# RX64M_MTU_Pilot register map
File version: 1.0
RX64M_MTU_Pilot peripheral registers generated from iodefine.h (pilot).
Registers are 8-bit, read-write, reset 0x0 unless marked. A register's access mark holds for its fields unless they carry their own. Offsets are from the block's base; lines under a group give offsets from that group; [hi:lo] are bit positions; {n}, {i} and the like mark numbered series; 'fields as' and 'values as' point back to an identical list; <NAME> marks a mode.

## Memory map
0x000C1200 MTU3 size 0x94
0x000C1200 MTU4 size 0x95
0x000C120A MTU size 0x87B
0x000C1290 MTU0 size 0x99
0x000C1290 MTU1 size 0x11C
0x000C1292 MTU2 size 0x17B
0x000C1A00 MTU6 size 0x94
0x000C1A00 MTU7 size 0x95
0x000C1A94 MTU5 size 0x223

## MTU
Base 0x000C120A
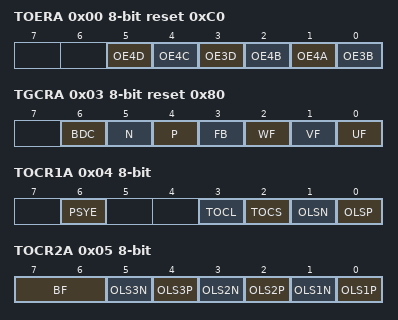
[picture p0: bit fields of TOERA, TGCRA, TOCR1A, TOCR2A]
0x00 TOERA reset 0xC0
  [5] OE4D, [4] OE4C, [3] OE3D, [2] OE4B, [1] OE4A, [0] OE3B
0x03 TGCRA reset 0x80
  [6] BDC, [5] N, [4] P, [3] FB, [2] WF, [1] VF, [0] UF
0x04 TOCR1A
  [6] PSYE, [3] TOCL, [2] TOCS, [1] OLSN, [0] OLSP
0x05 TOCR2A
  [7:6] BF, [5] OLS3N, [4] OLS3P, [3] OLS2N, [2] OLS2P, [1] OLS1N, [0] OLS1P
0x0A TCDRA 16-bit reset 0xFFFF
0x0C TDDRA 16-bit reset 0xFFFF
0x16 TCNTSA 16-bit ro
0x18 TCBRA 16-bit reset 0xFFFF
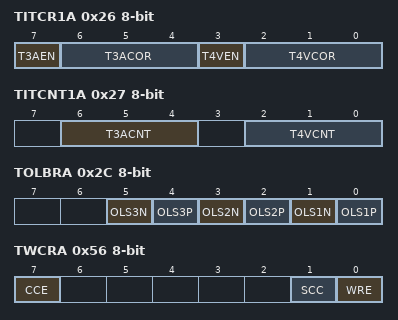
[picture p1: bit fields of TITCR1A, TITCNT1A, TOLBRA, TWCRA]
0x26 TITCR1A
  [7] T3AEN, [6:4] T3ACOR, [3] T4VEN, [2:0] T4VCOR
0x27 TITCNT1A ro
  [6:4] T3ACNT, [2:0] T4VCNT
0x28 TBTERA
  [1:0] BTE
0x2A TDERA reset 0x1
  [0] TDER
0x2C TOLBRA
  [5] OLS3N, [4] OLS3P, [3] OLS2N, [2] OLS2P, [1] OLS1N, [0] OLS1P
0x30 TITMRA
  [0] TITM
0x31 TITCR2A
  [2:0] TRG4COR
0x32 TITCNT2A ro
  [2:0] TRG4CNT
0x56 TWCRA
  [7] CCE, [1] SCC, [0] WRE
0x66 TMDR2A
  [0] DRS
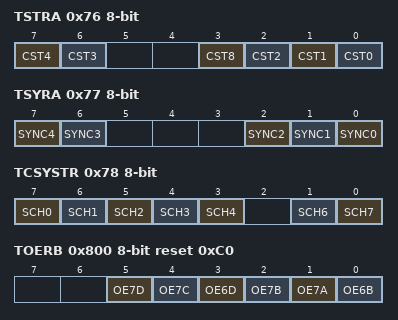
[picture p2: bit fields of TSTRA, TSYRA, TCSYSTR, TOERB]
0x76 TSTRA
  [7] CST4, [6] CST3, [3] CST8, [2] CST2, [1] CST1, [0] CST0
0x77 TSYRA
  [7] SYNC4, [6] SYNC3, [2] SYNC2, [1] SYNC1, [0] SYNC0
0x78 TCSYSTR
  [7-n] SCH{n} (n=0..4), [1] SCH6, [0] SCH7
0x7A TRWERA reset 0x1
  [0] RWE
0x800 TOERB reset 0xC0
  [5] OE7D, [4] OE7C, [3] OE6D, [2] OE7B, [1] OE7A, [0] OE6B
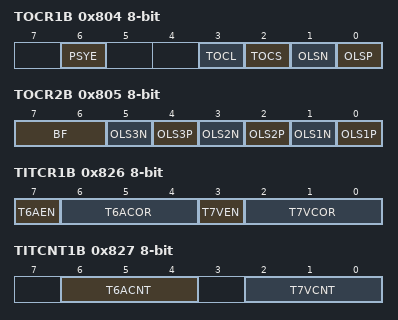
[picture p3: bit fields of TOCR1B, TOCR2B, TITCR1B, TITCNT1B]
0x804 TOCR1B
  [6] PSYE, [3] TOCL, [2] TOCS, [1] OLSN, [0] OLSP
0x805 TOCR2B
  fields as TOCR2A
0x80A TCDRB 16-bit reset 0xFFFF
0x80C TDDRB 16-bit reset 0xFFFF
0x816 TCNTSB 16-bit ro
0x818 TCBRB 16-bit reset 0xFFFF
0x826 TITCR1B
  [7] T6AEN, [6:4] T6ACOR, [3] T7VEN, [2:0] T7VCOR
0x827 TITCNT1B ro
  [6:4] T6ACNT, [2:0] T7VCNT
0x828 TBTERB
  [1:0] BTE
0x82A TDERB reset 0x1
  [0] TDER
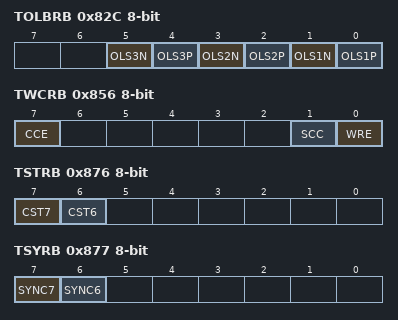
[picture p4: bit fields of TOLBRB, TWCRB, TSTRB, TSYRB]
0x82C TOLBRB
  [5] OLS3N, [4] OLS3P, [3] OLS2N, [2] OLS2P, [1] OLS1N, [0] OLS1P
0x830 TITMRB
  [0] TITM
0x831 TITCR2B
  [2:0] TRG7COR
0x832 TITCNT2B ro
  [2:0] TRG7CNT
0x856 TWCRB
  [7] CCE, [1] SCC, [0] WRE
0x866 TMDR2B
  [0] DRS
0x876 TSTRB
  [7] CST7, [6] CST6
0x877 TSYRB
  [7] SYNC7, [6] SYNC6
0x87A TRWERB reset 0x1
  [0] RWE

## MTU0
Base 0x000C1290
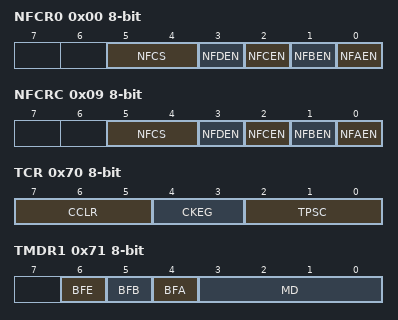
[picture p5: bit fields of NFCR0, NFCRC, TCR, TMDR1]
0x00 NFCR0
  [5:4] NFCS, [3] NFDEN, [2] NFCEN, [1] NFBEN, [0] NFAEN
0x09 NFCRC
  [5:4] NFCS, [3] NFDEN, [2] NFCEN, [1] NFBEN, [0] NFAEN
0x70 TCR
  [7:5] CCLR, [4:3] CKEG, [2:0] TPSC
0x71 TMDR1
  [6] BFE, [5] BFB, [4] BFA, [3:0] MD
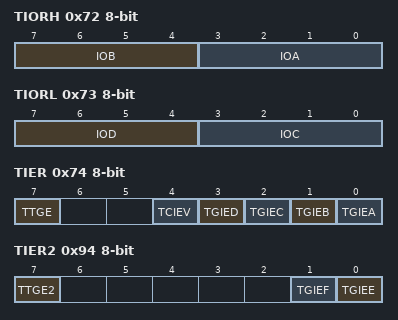
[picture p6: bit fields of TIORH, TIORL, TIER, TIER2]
0x72 TIORH
  [7:4] IOB, [3:0] IOA
0x73 TIORL
  [7:4] IOD, [3:0] IOC
0x74 TIER
  [7] TTGE, [4] TCIEV, [3] TGIED, [2] TGIEC, [1] TGIEB, [0] TGIEA
0x76 TCNT 16-bit
0x78 TGRA 16-bit reset 0xFFFF
0x7A TGRB 16-bit reset 0xFFFF
0x7C TGRC 16-bit reset 0xFFFF
0x7E TGRD 16-bit reset 0xFFFF
0x90 TGRE 16-bit reset 0xFFFF
0x92 TGRF 16-bit reset 0xFFFF
0x94 TIER2
  [7] TTGE2, [1] TGIEF, [0] TGIEE
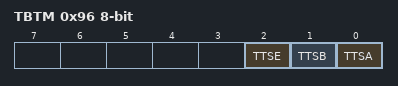
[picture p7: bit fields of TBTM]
0x96 TBTM
  [2] TTSE, [1] TTSB, [0] TTSA
0x98 TCR2
  [2:0] TPSC2

## MTU1
Base 0x000C1290; alternate view of MTU0
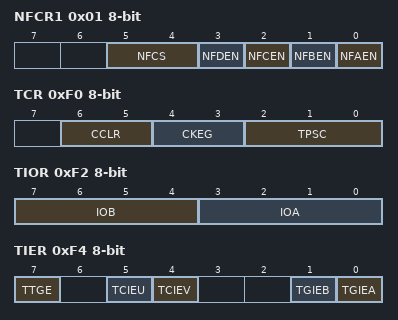
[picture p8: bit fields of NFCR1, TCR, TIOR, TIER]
0x01 NFCR1
  [5:4] NFCS, [3] NFDEN, [2] NFCEN, [1] NFBEN, [0] NFAEN
0xF0 TCR
  [6:5] CCLR, [4:3] CKEG, [2:0] TPSC
0xF1 TMDR1
  [3:0] MD
0xF2 TIOR
  [7:4] IOB, [3:0] IOA
0xF4 TIER
  [7] TTGE, [5] TCIEU, [4] TCIEV, [1] TGIEB, [0] TGIEA
0xF5 TSR reset 0xC0
  [7] TCFD
0xF6 TCNT 16-bit
0xF8 TGRA 16-bit reset 0xFFFF
0xFA TGRB 16-bit reset 0xFFFF
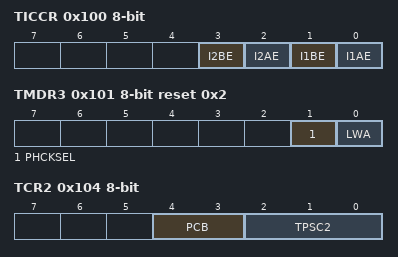
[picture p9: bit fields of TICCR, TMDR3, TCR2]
0x100 TICCR
  [3] I2BE, [2] I2AE, [1] I1BE, [0] I1AE
0x101 TMDR3 reset 0x2
  [1] PHCKSEL, [0] LWA
0x104 TCR2
  [4:3] PCB, [2:0] TPSC2
0x110 TCNTLW 32-bit
0x114 TGRALW 32-bit reset 0xFFFFFFFF
0x118 TGRBLW 32-bit reset 0xFFFFFFFF

## MTU2
Base 0x000C1292
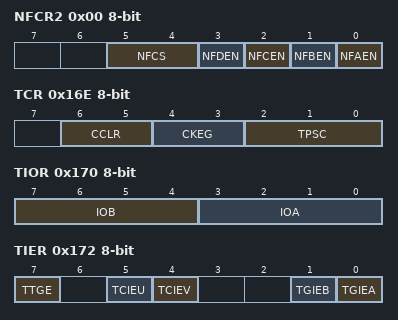
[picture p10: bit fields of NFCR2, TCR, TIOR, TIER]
0x00 NFCR2
  [5:4] NFCS, [3] NFDEN, [2] NFCEN, [1] NFBEN, [0] NFAEN
0x16E TCR
  [6:5] CCLR, [4:3] CKEG, [2:0] TPSC
0x16F TMDR1
  [3:0] MD
0x170 TIOR
  [7:4] IOB, [3:0] IOA
0x172 TIER
  [7] TTGE, [5] TCIEU, [4] TCIEV, [1] TGIEB, [0] TGIEA
0x173 TSR reset 0xC0
  [7] TCFD
0x174 TCNT 16-bit
0x176 TGRA 16-bit reset 0xFFFF
0x178 TGRB 16-bit reset 0xFFFF
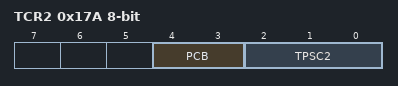
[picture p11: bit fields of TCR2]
0x17A TCR2
  [4:3] PCB, [2:0] TPSC2

## MTU3
Base 0x000C1200
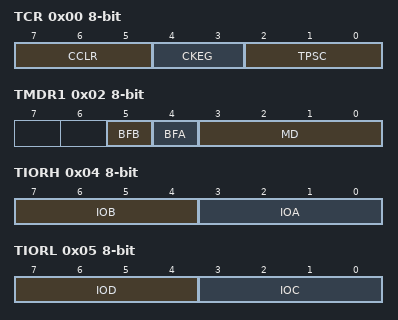
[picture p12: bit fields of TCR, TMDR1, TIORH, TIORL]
0x00 TCR
  [7:5] CCLR, [4:3] CKEG, [2:0] TPSC
0x02 TMDR1
  [5] BFB, [4] BFA, [3:0] MD
0x04 TIORH
  [7:4] IOB, [3:0] IOA
0x05 TIORL
  [7:4] IOD, [3:0] IOC
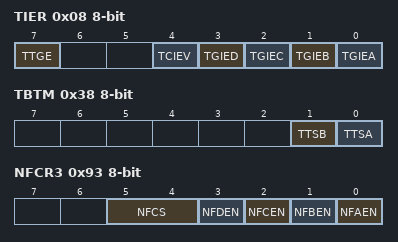
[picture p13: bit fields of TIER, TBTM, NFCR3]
0x08 TIER
  [7] TTGE, [4] TCIEV, [3] TGIED, [2] TGIEC, [1] TGIEB, [0] TGIEA
0x10 TCNT 16-bit
0x18 TGRA 16-bit reset 0xFFFF
0x1A TGRB 16-bit reset 0xFFFF
0x24 TGRC 16-bit reset 0xFFFF
0x26 TGRD 16-bit reset 0xFFFF
0x2C TSR reset 0xC0
  [7] TCFD
0x38 TBTM
  [1] TTSB, [0] TTSA
0x4C TCR2
  [2:0] TPSC2
0x72 TGRE 16-bit reset 0xFFFF
0x93 NFCR3
  [5:4] NFCS, [3] NFDEN, [2] NFCEN, [1] NFBEN, [0] NFAEN

## MTU4
Base 0x000C1200; alternate view of MTU3
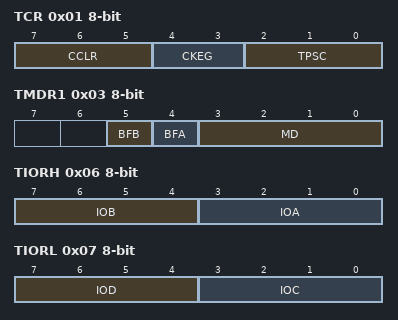
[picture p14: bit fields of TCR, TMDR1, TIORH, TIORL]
0x01 TCR
  [7:5] CCLR, [4:3] CKEG, [2:0] TPSC
0x03 TMDR1
  [5] BFB, [4] BFA, [3:0] MD
0x06 TIORH
  [7:4] IOB, [3:0] IOA
0x07 TIORL
  [7:4] IOD, [3:0] IOC
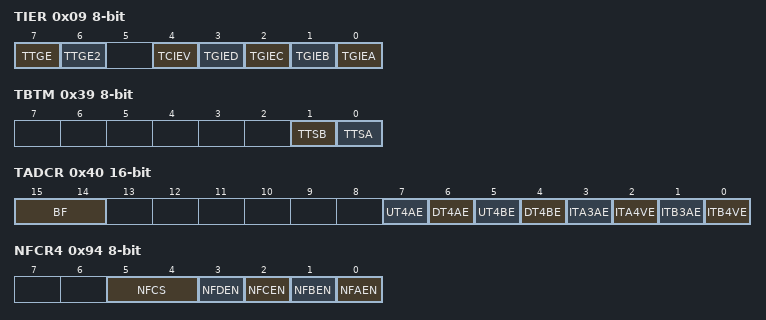
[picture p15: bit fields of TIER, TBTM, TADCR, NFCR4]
0x09 TIER
  [7] TTGE, [6] TTGE2, [4] TCIEV, [3] TGIED, [2] TGIEC, [1] TGIEB, [0] TGIEA
0x12 TCNT 16-bit
0x1C TGRA 16-bit reset 0xFFFF
0x1E TGRB 16-bit reset 0xFFFF
0x28 TGRC 16-bit reset 0xFFFF
0x2A TGRD 16-bit reset 0xFFFF
0x2D TSR reset 0xC0
  [7] TCFD
0x39 TBTM
  [1] TTSB, [0] TTSA
0x40 TADCR 16-bit
  [15:14] BF, [7] UT4AE, [6] DT4AE, [5] UT4BE, [4] DT4BE, [3] ITA3AE, [2] ITA4VE, [1] ITB3AE, [0] ITB4VE
0x44 TADCORA 16-bit reset 0xFFFF
0x46 TADCORB 16-bit reset 0xFFFF
0x48 TADCOBRA 16-bit reset 0xFFFF
0x4A TADCOBRB 16-bit reset 0xFFFF
0x4D TCR2
  [2:0] TPSC2
0x74 TGRE 16-bit reset 0xFFFF
0x76 TGRF 16-bit reset 0xFFFF
0x94 NFCR4
  [5:4] NFCS, [3] NFDEN, [2] NFCEN, [1] NFBEN, [0] NFAEN

## MTU5
Base 0x000C1A94
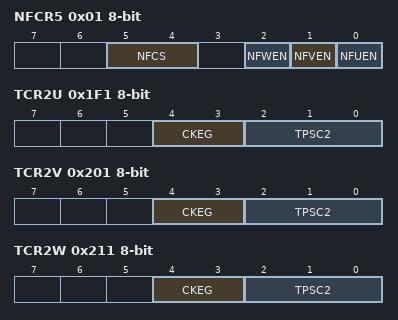
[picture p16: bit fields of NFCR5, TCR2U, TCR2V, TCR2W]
0x01 NFCR5
  [5:4] NFCS, [2] NFWEN, [1] NFVEN, [0] NFUEN
0x1EC TCNTU 16-bit
0x1EE TGRU 16-bit reset 0xFFFF
0x1F0 TCRU
  [1:0] TPSC
0x1F1 TCR2U
  [4:3] CKEG, [2:0] TPSC2
0x1F2 TIORU
  [4:0] IOC
0x1FC TCNTV 16-bit
0x1FE TGRV 16-bit reset 0xFFFF
0x200 TCRV
  [1:0] TPSC
0x201 TCR2V
  [4:3] CKEG, [2:0] TPSC2
0x202 TIORV
  [4:0] IOC
0x20C TCNTW 16-bit
0x20E TGRW 16-bit reset 0xFFFF
0x210 TCRW
  [1:0] TPSC
0x211 TCR2W
  [4:3] CKEG, [2:0] TPSC2
0x212 TIORW
  [4:0] IOC
0x21E TIER
  [2] TGIE5U, [1] TGIE5V, [0] TGIE5W
0x220 TSTR
  [2] CSTU5, [1] CSTV5, [0] CSTW5
0x222 TCNTCMPCLR
  [2] CMPCLR5U, [1] CMPCLR5V, [0] CMPCLR5W

## MTU6
Base 0x000C1A00
Registers as MTU3, without NFCR3; these are added or differ:
0x50 TSYCR
  [7] CE0A, [6] CE0B, [5] CE0C, [4] CE0D, [3] CE1A, [2] CE1B, [1] CE2A, [0] CE2B
0x93 NFCR6
  [5:4] NFCS, [3] NFDEN, [2] NFCEN, [1] NFBEN, [0] NFAEN

## MTU7
Base 0x000C1A00; alternate view of MTU6
Registers as MTU4, without NFCR4; these are added or differ:
0x40 TADCR 16-bit
  [15:14] BF, [7] UT7AE, [6] DT7AE, [5] UT7BE, [4] DT7BE, [3] ITA6AE, [2] ITA7VE, [1] ITB6AE, [0] ITB7VE
0x94 NFCR7
  [5:4] NFCS, [3] NFDEN, [2] NFCEN, [1] NFBEN, [0] NFAEN
